# V32F20x_CM33 register map
File version: 1.0.3
CPU: CM33 r0p4, little endian, MPU, FPU, DSP, 3 interrupt priority bits, 8 SAU regions
Registers are 32-bit, read-write, reset 0x0 unless marked. A register's access mark holds for its fields unless they carry their own. Offsets are from the block's base; [hi:lo] are bit positions; {n}, {i} and the like mark numbered series.

## VGIO — VGIO Peripheral Interface
Base 0x40107000
Same registers: SEC_VGIO 0x50107000
{0x0+4i} BOTTOM{i} (i=0..31) — VGIO configure register on bottom side
  [31:0] BOTTOM
{0x100+4i} RIGHT{i} (i=0..31) — VGIO configure register on right side
  [31:0] RIGHT
{0x200+4i} TOP{i} (i=0..31) — VGIO configure register on top side
  [31:0] TOP
{0x300+4i} LEFT{i} (i=0..31) — VGIO configure register on left side
  [31:0] BOTTOM

## WAVER — WAVER Peripheral Interface
Base 0x21014000
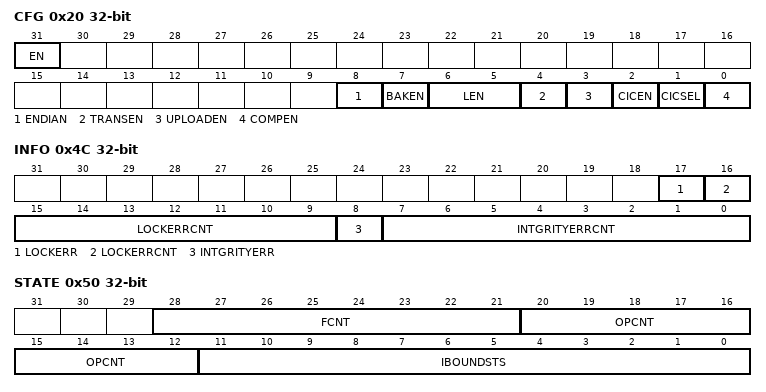
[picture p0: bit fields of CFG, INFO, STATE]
0x20 CFG — WAVER configuration register
  [31] EN — WAVER module enable control.
  [8] ENDIAN — Endian configuration.
  [7] BAKEN — The backup waveform for CM0 processing control.
  [6:5] LEN — The number of samples per-cycle.
  [4] TRANSEN — Transport the upload Waveform to CM33 system enable control
  [3] UPLOADEN — Waveform sample upload enable control.
  [2] CICEN — CIC Down sample enable.
  [1] CICSEL — Down sample rate selection.
  [0] COMPEN — Compensation enable control.
0x30 MODE — WAVER mode configuration register
  [1:0] MODE — Waver mode configuration.
0x40 DATA — WAVER data register
  [31:0] DATA — Sample data buffer candidate for FFT analysis.
0x4C INFO — WAVER information register
  [17] LOCKERR — A Lock Error has been occur between two cycles wave
  [16:9] LOCKERRCNT — Flame count of Lock Error cycles.
  [8] INTGRITYERR — An integrity error occurred while receiving data.
  [7:0] INTGRITYERRCNT — Flame count of Integrity Error cycles.
0x50 STATE — WAVER state register
  [28:21] FCNT — Current flame count.
  [20:12] OPCNT — Current operation count (max 256).
  [11:0] IBOUNDSTS — Integrity Error occur on IB SPI0 interface.

## BSPI0 — BSPI0 Peripheral Interface
Base 0x41020000
Same registers: BSPI1 0x41020800, BSPI2 0x41021000, BSPI3 0x41021800, BSPI4 0x41022000, BSPI5 0x41022800
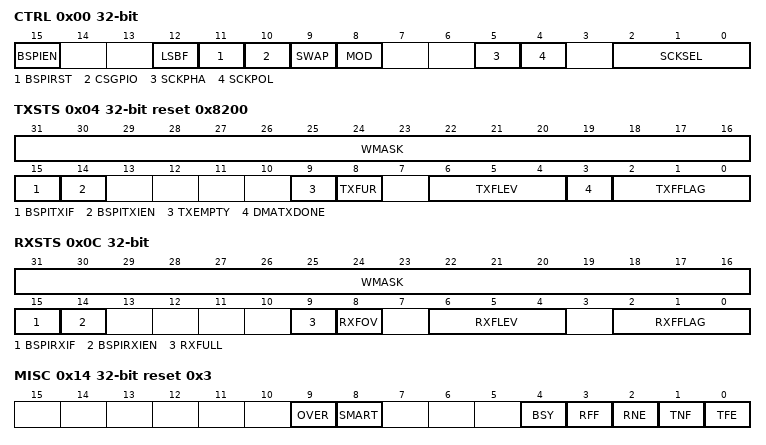
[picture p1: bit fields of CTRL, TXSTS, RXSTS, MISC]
0x00 CTRL — BSPI control Register
  [15] BSPIEN — BSPI enable.
  [12] LSBF — BSPI LSB control.
  [11] BSPIRST — BSPI software reset.
  [10] CSGPIO — The control owner of BSPICS.
  [9] SWAP — BSPI MISO/MOSI swap control.
  [8] MOD — BSPI Mode Selection register.
  [5] SCKPHA — BSPI clock phase.
  [4] SCKPOL — BSPI clock polarity.
  [2:0] SCKSEL — Master mode clock selection.
0x04 TXSTS reset 0x8200 — BSPI transmit status register
  [31:16] WMASK — Write mask bit
  [15] BSPITXIF — BSPI Transmit Interrupt flag.
  [14] BSPITXIEN — BSPI Transmit Interrupt Enable.
  [9] TXEMPTY — Transmot FIFO empty register.
  [8] TXFUR — Transmit FIFO under run register.
  [6:4] TXFLEV — Transmit FIFO interrupt level register.
  [3] DMATXDONE — Transfer done flag will auto set 1 after transmit all the data
  [2:0] TXFFLAG — Transmit FIFO Data Level.
0x08 TXDAT wo — BSPI transmit FIFO register
  [7:0] BSPITXDATA — Write data to BSPI Transmit FIFO.
0x0C RXSTS — BSPI receive status register
  [31:16] WMASK — Write mask bit
  [15] BSPIRXIF — BSPI Transmit Interrupt flag.
  [14] BSPIRXIEN — BSPI Receive Interrupt Enable.
  [9] RXFULL — Receive FIFO full register.
  [8] RXFOV — Receive FIFO over run register.
  [6:4] RXFLEV — Receive FIFO interrupt level register.
  [2:0] RXFFLAG — Receive FIFO Data Level.
0x10 RXDAT ro — BSPI receive FIFO register
  [7:0] BSPIRXDATA — Read data from BSPI Receive Buffer.
0x14 MISC reset 0x3 — BSPI Misc. control register
  [9] OVER — BSPI FIFO over write mode enable control.
  [8] SMART — BSPI FIFO smart mode control.
  [4] BSY — BSPI Controller busy flag.
  [3] RFF — Receive FIFO full flag.
  [2] RNE — Receive FIFO Not Empty Flag.
  [1] TNF — Transmit FIFO Not Full Flag.
  [0] TFE — Transmit FIFO empty flag.

## BDMA — BDMA Peripheral Interface
Base 0x41080800
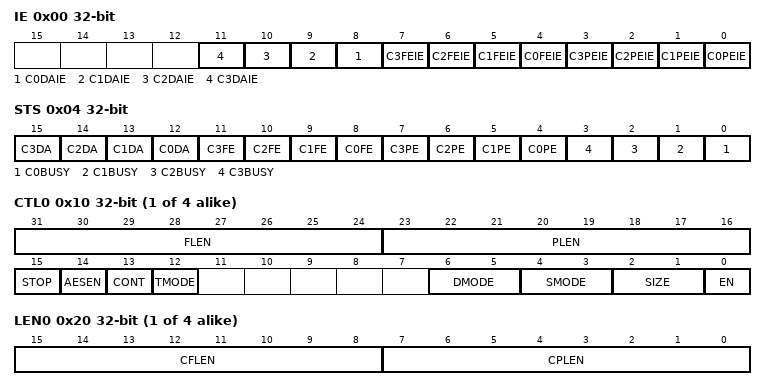
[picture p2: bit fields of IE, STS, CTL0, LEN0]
0x00 IE — BDMA interrupt enable register.
  [n+8] C{n}DAIE (n=0..3) — Channel {n} data abort interrupt enable
  [n+4] C{n}FEIE (n=0..3) — Channel {n} frame end interrupt enable
  [n] C{n}PEIE (n=0..3) — Channel {n} package end interrupt enable
0x04 STS — BDMA status register.
  [n+12] C{n}DA (n=0..3) — Channel {n} data about interrupt flag.
  [n+8] C{n}FE (n=0..3) — Channel {n} frame end interrupt flag.
  [n+4] C{n}PE (n=0..3) — Channel {n} package end interrupt flag.
  [n] C{n}BUSY (n=0..3) — DMA channel {n} busy
{0x10+0x20*i} CTL{i} (i=0..3) — BDMA channel x control register.
  [31:24] FLEN — Frame length
  [23:16] PLEN — Package length
  [15] STOP — Force stop DMA transfer
  [14] AESEN — Enable AES encrypt/decrypt function of DMA channel
  [13] CONT — Continuous mode
  [12] TMODE — Transfer mode selection
  [6:5] DMODE — Destination address mode
  [4:3] SMODE — Source address mode
  [2:1] SIZE — Transfer size mode
  [0] EN — DMA channel enable
{0x14+0x20*i} SEL{i} (i=0..3) — BDMA channel x request select.
  [5:0] DMASEL — DMA request source selection
{0x18+0x20*i} SRC{i} (i=0..3) — BDMA channel x source address register.
  [31:0] SRC — Source address register.
{0x1C+0x20*i} DST{i} (i=0..3) — BDMA channel x destination address register.
  [31:0] DST — Source address register.
{0x20+0x20*i} LEN{i} ro (i=0..3) — BDMA channel x transfer length register.
  [15:8] CFLEN — Current frame transferred length.
  [7:0] CPLEN — Current package transferred length.
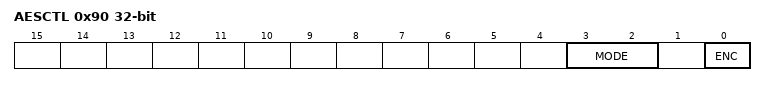
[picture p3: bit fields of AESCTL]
0x90 AESCTL — BDMA AES control register.
  [3:2] MODE — AES mode selection register.
  [0] ENC — AES encode/decode selection register.
{0xA0+4i} AESKEY{i} (i=0..7) — BDMA AES key x register.
  [31:0] KEYx — AES KEY register.
